AUTOSAR XML (schema 4-3-0)
package /Impl_SWC_DDM_ARPkg
  swc implementation Impl_SWC_DDM_type: programming-language=C, sw-version=1.0.0, vendor-id=0, behavior=SWC_DDM_type_IB
    code-descriptors:
      code SRC: artifact-descriptors=autosar-engineering-object={short-label=EngObject, category=SWSRC}
    resource consumption ResourceConsumption
      memory section MEM_SWC_DDM_CAL: size=0, sw-addrmethod=CAL, symbol=CAL
      memory section MEM_SWC_DDM_CODE: size=0, sw-addrmethod=CODE, symbol=CODE
package /SWC_DDM_ARPkg
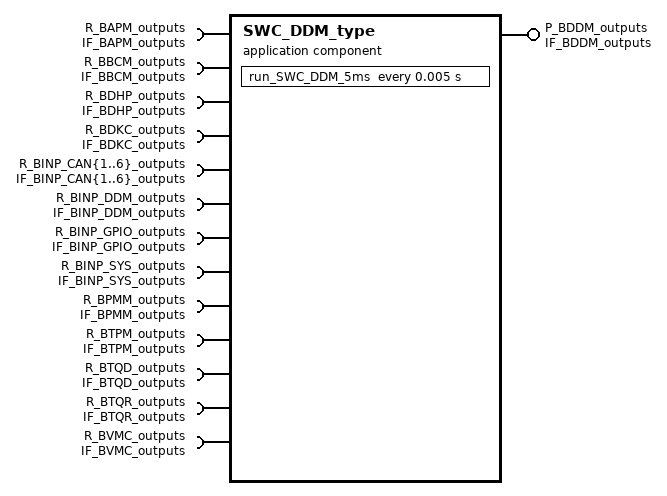
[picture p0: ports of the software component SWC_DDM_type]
  application sw component type SWC_DDM_type
    provide port P_BDDM_outputs: provided-interface=IF_BDDM_outputs
    18 x require port:
      R_BAPM_outputs: required-interface=IF_BAPM_outputs
      R_BBCM_outputs: required-interface=IF_BBCM_outputs
      R_BDHP_outputs: required-interface=IF_BDHP_outputs
      R_BDKC_outputs: required-interface=IF_BDKC_outputs
      R_BINP_CAN{1..6}_outputs: required-interface=IF_BINP_CAN{1..6}_outputs
      R_BINP_DDM_outputs: required-interface=IF_BINP_DDM_outputs
      R_BINP_GPIO_outputs: required-interface=IF_BINP_GPIO_outputs
      R_BINP_SYS_outputs: required-interface=IF_BINP_SYS_outputs
      R_BPMM_outputs: required-interface=IF_BPMM_outputs
      R_BTPM_outputs: required-interface=IF_BTPM_outputs
      R_BTQD_outputs: required-interface=IF_BTQD_outputs
      R_BTQR_outputs: required-interface=IF_BTQR_outputs
      R_BVMC_outputs: required-interface=IF_BVMC_outputs
    behavior SWC_DDM_type_IB: data-type-mapping=AppModeTypeMap, handle-termination-and-restart=NO-SUPPORT
      timing event TE_DDM_5ms: start-on-event=run_SWC_DDM_5ms, period=0.005
      runnable run_SWC_DDM_5ms
        data-receive-point-by-arguments:
          18 x access:
            drparg_BAPM_outputs: accessed-variable=R_BAPM_outputs.BAPM_outputs
            drparg_BBCM_outputs: accessed-variable=R_BBCM_outputs.BBCM_outputs
            drparg_BDHP_outputs: accessed-variable=R_BDHP_outputs.BDHP_outputs
            drparg_BDKC_outputs: accessed-variable=R_BDKC_outputs.BDKC_outputs
            drparg_BINP_CAN{1..6}_outputs: accessed-variable=R_BINP_CAN{1..6}_outputs.BINP_CAN{1..6}_outputs
            drparg_BINP_DDM_outputs: accessed-variable=R_BINP_DDM_outputs.BINP_DDM_outputs
            drparg_BINP_GPIO_outputs: accessed-variable=R_BINP_GPIO_outputs.BINP_GPIO_outputs
            drparg_BINP_SYS_outputs: accessed-variable=R_BINP_SYS_outputs.BINP_SYS_outputs
            drparg_BPMM_outputs: accessed-variable=R_BPMM_outputs.BPMM_outputs
            drparg_BTPM_outputs: accessed-variable=R_BTPM_outputs.BTPM_outputs
            drparg_BTQD_outputs: accessed-variable=R_BTQD_outputs.BTQD_outputs
            drparg_BTQR_outputs: accessed-variable=R_BTQR_outputs.BTQR_outputs
            drparg_BVMC_outputs: accessed-variable=R_BVMC_outputs.BVMC_outputs
        data-send-points:
          access dsp_BDDM_outputs: accessed-variable=P_BDDM_outputs.BDDM_outputs
